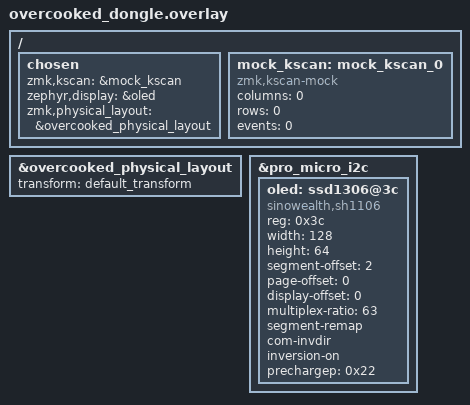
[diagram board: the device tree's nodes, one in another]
#include "overcooked.dtsi"


&overcooked_physical_layout {
    transform = <&default_transform>;
};

/ {
    chosen {
        zmk,kscan = &mock_kscan;
        zephyr,display = &oled;
        zmk,physical_layout = &overcooked_physical_layout;
    };

    mock_kscan: mock_kscan_0 {
        compatible = "zmk,kscan-mock";
        columns = <0>;
        rows = <0>;
        events = <0>;
    };

};

/delete-node/ &kscan0;

&pro_micro_i2c {
    status = "okay";
    
    oled: ssd1306@3c {
        compatible = "sinowealth,sh1106";
        reg = <0x3c>;
        width = <128>;
        height = <64>;
        segment-offset = <2>;
        page-offset = <0>;
        display-offset = <0>;
        multiplex-ratio = <63>;
        segment-remap;
        com-invdir;
        inversion-on;
        prechargep = <0x22>;
    };
};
